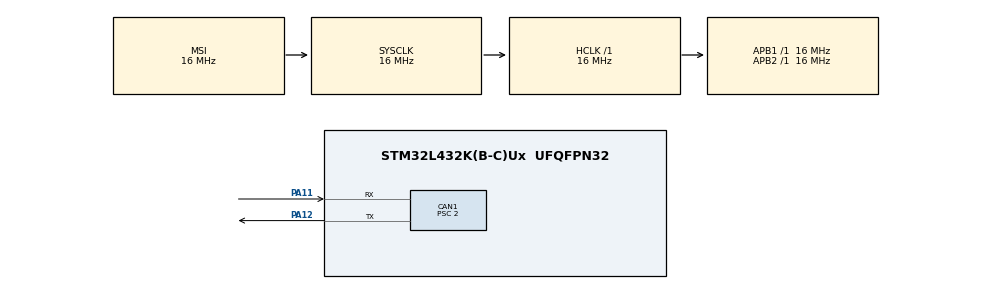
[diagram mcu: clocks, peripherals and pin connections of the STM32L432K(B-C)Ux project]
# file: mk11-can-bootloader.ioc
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CAN1.BS1=CAN_BS1_13TQ
CAN1.BS2=CAN_BS2_2TQ
CAN1.CalculateBaudRate=500000
CAN1.CalculateTimeBit=2000
CAN1.CalculateTimeQuantum=125.0
CAN1.Prescaler=2
Mcu.Family=STM32L4
Mcu.Name=STM32L432K(B-C)Ux
Mcu.Package=UFQFPN32
NVIC.CAN1_RX0_IRQn=true\:0\:0\:false\:false\:true\:true\:true\:true
NVIC.PriorityGroup=NVIC_PRIORITYGROUP_4
PA11.GPIO_PuPd=GPIO_PULLUP
PA11.Mode=CAN_Activate
PA11.Signal=CAN1_RX
PA12.Mode=CAN_Activate
PA12.Signal=CAN1_TX
ProjectManager.HeapSize=0x200
ProjectManager.StackSize=0x400
ProjectManager.TargetToolchain=STM32CubeIDE
RCC.ADCFreq_Value=64000000
RCC.AHBFreq_Value=16000000
RCC.APB1Freq_Value=16000000
RCC.APB1TimFreq_Value=16000000
RCC.APB2Freq_Value=16000000
RCC.APB2TimFreq_Value=16000000
RCC.CortexFreq_Value=16000000
RCC.HCLKFreq_Value=16000000
RCC.HSE_VALUE=8000000
RCC.HSI48_VALUE=48000000
RCC.HSI_VALUE=16000000
RCC.LSE_VALUE=32768
RCC.MSIClockRange=RCC_MSIRANGE_8
RCC.MSI_VALUE=16000000
RCC.SYSCLKFreq_VALUE=16000000
RCC.USBFreq_Value=64000000
RCC.VCOOutputFreq_Value=128000000
board=custom

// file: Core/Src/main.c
/* USER CODE BEGIN Header */
/**
  ******************************************************************************
  * @file           : main.c
  * @brief          : Main program body
  ******************************************************************************
  * @attention
  *
  * Copyright (c) 2025 STMicroelectronics.
  * All rights reserved.
  *
  * This software is licensed under terms that can be found in the LICENSE file
  * in the root directory of this software component.
  * If no LICENSE file comes with this software, it is provided AS-IS.
  *
  ******************************************************************************
  */
/* USER CODE END Header */
#include "main.h"
#include "can.h"
#include "gpio.h"

/* USER CODE BEGIN Includes */
#include "stdbool.h"
/* USER CODE END Includes */

/* USER CODE BEGIN PD */
#define BOOTLOADER_ADDR 0x08000000
#define APPLICATION_ADDR 0x08004000

#define REQUEST_FIRMWARE_UPDATE_ID 0x0F1
#define FIRMWARE_UPDATE_DATA_ID 0xFD

#define MICROCONTROLLER_ACK 0x01
#define MICROCONTROLLER_ID 0x43

#define BOOTLOADER_TIMEOUT 15000
/* USER CODE END PD */

/* USER CODE BEGIN PV */
int count = 0;
HAL_StatusTypeDef status;

uint32_t TxMailbox;
CAN_TxHeaderTypeDef TxHeader;
uint8_t TxData[8];

CAN_RxHeaderTypeDef RxHeader;
uint8_t RxData[8];
uint32_t start_time;

bool bootload_requested;
/* USER CODE END PV */

void SystemClock_Config(void);
/* USER CODE BEGIN PFP */
bool check_bootmode(void);
void go_to_application(void);
void process_command(CAN_RxHeaderTypeDef*, uint8_t*);
void send_ack_message(CAN_TxHeaderTypeDef*, uint8_t*);
void flash_firmware();
/* USER CODE END PFP */

/* USER CODE BEGIN 0 */

bool check_bootmode(void) {
	return 1;
	// Done for now
}

void go_to_application(void) {
	// Adjusting MSP and Reset Handler Pointer
	uint32_t app_sp = *(volatile uint32_t*)APPLICATION_ADDR;
	__set_MSP(app_sp);

	uint32_t app_pc = *(volatile uint32_t*)(APPLICATION_ADDR + 4);
	void (*app_reset_handler)(void) = (void*)app_pc;
	app_reset_handler();
}

void HAL_CAN_RxFifo0MsgPendingCallback(CAN_HandleTypeDef *hcan) {
	if (HAL_CAN_GetRxMessage(hcan, CAN_RX_FIFO0, &RxHeader, RxData) != HAL_OK) {
		return;
	}
	count++;
	process_command(&RxHeader, RxData);
}

void process_command(CAN_RxHeaderTypeDef* rx_header, uint8_t* rx_data) {
	// TODO: Proper handling for the actual firmware update
	if (rx_header->StdId == REQUEST_FIRMWARE_UPDATE_ID && rx_data[0] == MICROCONTROLLER_ID) {
		bootload_requested = 1;
		send_ack_message(&TxHeader, TxData);
	}
}

void send_ack_message(CAN_TxHeaderTypeDef* tx_header, uint8_t* tx_data) {
	tx_header->IDE = CAN_ID_STD;
	tx_header->StdId = MICROCONTROLLER_ACK;
	tx_header->RTR = CAN_RTR_DATA;
	tx_header->DLC = 2;

	tx_data[0] = MICROCONTROLLER_ID;
	tx_data[1] = 0x01;

	HAL_CAN_AddTxMessage(&hcan1, tx_header, tx_data, &TxMailbox);
}

void flash_firmware() {
	// TODO: Rewrite the flash memory..
}

/* USER CODE END 0 */

int main(void)
{

  /* MCU Configuration--------------------------------------------------------*/

  /* Reset of all peripherals, Initializes the Flash interface and the Systick. */
  HAL_Init();

  /* Configure the system clock */
  SystemClock_Config();

  /* Initialize all configured peripherals */
  MX_GPIO_Init();
  MX_CAN1_Init();
  /* USER CODE BEGIN 2 */

//  if (!checkBootmode()) {
//	  // TODO: Adjusting checkBootmode()
//	  jump_to_application();
//  }

//  start_time = HAL_GetTick();

  CAN_FilterTypeDef sFilterConfig;

  sFilterConfig.FilterBank = 0;
  sFilterConfig.FilterMode = CAN_FILTERMODE_IDMASK;
  sFilterConfig.FilterScale = CAN_FILTERSCALE_32BIT;
  sFilterConfig.FilterIdHigh = 0x0000;
  sFilterConfig.FilterIdLow = 0x0000;
  sFilterConfig.FilterMaskIdHigh = 0x0000;
  sFilterConfig.FilterMaskIdLow = 0x0000;
  sFilterConfig.FilterFIFOAssignment = CAN_RX_FIFO0;
  sFilterConfig.FilterActivation = ENABLE;
  sFilterConfig.SlaveStartFilterBank = 14;

  HAL_CAN_ConfigFilter(&hcan1, &sFilterConfig);

  HAL_CAN_Start(&hcan1);
  HAL_CAN_ActivateNotification(&hcan1, CAN_IT_RX_FIFO0_MSG_PENDING);

// TODO: A proper firmware update sequence
//  while (HAL_GetTick() - start_time < BOOTLOADER_TIMEOUT) {
//	  if (bootload_requested) {
//		  send_ack_message();
//		  flash_firmware();
//	  }
//  }
//
//  jump_to_application(); // In case of timeout, just jump to application

  /* USER CODE END 2 */

  /* Infinite loop */
  /* USER CODE BEGIN WHILE */
  while (1)
  {
//	  send_ack_message(&TxHeader, TxData);

    /* USER CODE END WHILE */

  }
}

void SystemClock_Config(void)
{
  RCC_OscInitTypeDef RCC_OscInitStruct = {0};
  RCC_ClkInitTypeDef RCC_ClkInitStruct = {0};

  /** Configure the main internal regulator output voltage
  */
  if (HAL_PWREx_ControlVoltageScaling(PWR_REGULATOR_VOLTAGE_SCALE1) != HAL_OK)
  {
    Error_Handler();
  }

  /** Initializes the RCC Oscillators according to the specified parameters
  * in the RCC_OscInitTypeDef structure.
  */
  RCC_OscInitStruct.OscillatorType = RCC_OSCILLATORTYPE_MSI;
  RCC_OscInitStruct.MSIState = RCC_MSI_ON;
  RCC_OscInitStruct.MSICalibrationValue = 0;
  RCC_OscInitStruct.MSIClockRange = RCC_MSIRANGE_8;
  RCC_OscInitStruct.PLL.PLLState = RCC_PLL_NONE;
  if (HAL_RCC_OscConfig(&RCC_OscInitStruct) != HAL_OK)
  {
    Error_Handler();
  }

  /** Initializes the CPU, AHB and APB buses clocks
  */
  RCC_ClkInitStruct.ClockType = RCC_CLOCKTYPE_HCLK|RCC_CLOCKTYPE_SYSCLK
                              |RCC_CLOCKTYPE_PCLK1|RCC_CLOCKTYPE_PCLK2;
  RCC_ClkInitStruct.SYSCLKSource = RCC_SYSCLKSOURCE_MSI;
  RCC_ClkInitStruct.AHBCLKDivider = RCC_SYSCLK_DIV1;
  RCC_ClkInitStruct.APB1CLKDivider = RCC_HCLK_DIV1;
  RCC_ClkInitStruct.APB2CLKDivider = RCC_HCLK_DIV1;

  if (HAL_RCC_ClockConfig(&RCC_ClkInitStruct, FLASH_LATENCY_0) != HAL_OK)
  {
    Error_Handler();
  }
}

void Error_Handler(void)
{
  __disable_irq();
  while (1)
  {
  }
}
